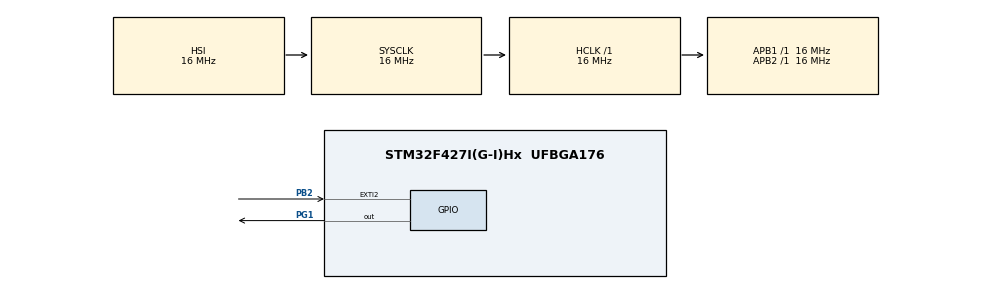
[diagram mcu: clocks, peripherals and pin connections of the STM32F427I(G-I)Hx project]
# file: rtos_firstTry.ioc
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FREERTOS.Tasks01=LEDTask,-3,128,LED_Task,Default,NULL,Dynamic,NULL,NULL;keyTask,-3,128,key_Task,Default,NULL,Dynamic,NULL,NULL
Mcu.Family=STM32F4
Mcu.Name=STM32F427I(G-I)Hx
Mcu.Package=UFBGA176
NVIC.EXTI2_IRQn=true\:5\:0\:false\:false\:true\:true\:true\:true
NVIC.PriorityGroup=NVIC_PRIORITYGROUP_4
NVIC.TIM1_UP_TIM10_IRQn=true\:0\:0\:false\:false\:true\:false\:false\:true
NVIC.TimeBase=TIM1_UP_TIM10_IRQn
NVIC.TimeBaseIP=TIM1
PA13.Mode=Serial_Wire
PA13.Signal=SYS_JTMS-SWDIO
PA14.Mode=Serial_Wire
PA14.Signal=SYS_JTCK-SWCLK
PB2/BOOT1.GPIO_ModeDefaultEXTI=GPIO_MODE_IT_RISING_FALLING
PB2/BOOT1.Signal=GPXTI2
PG1.Signal=GPIO_Output
ProjectManager.HeapSize=0x200
ProjectManager.StackSize=0x400
ProjectManager.TargetToolchain=MDK-ARM V5
RCC.AHBFreq_Value=16000000
RCC.APB1Freq_Value=16000000
RCC.APB2Freq_Value=16000000
RCC.CortexFreq_Value=16000000
RCC.HSE_VALUE=25000000
RCC.HSI_VALUE=16000000
RCC.LSE_VALUE=32768
RCC.SYSCLKFreq_VALUE=16000000
RCC.VCOOutputFreq_Value=192000000
VP_FREERTOS_VS_CMSIS_V1.Mode=CMSIS_V1
VP_SYS_VS_tim1.Mode=TIM1
board=custom

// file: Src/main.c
/* USER CODE BEGIN Header */
/**
  ******************************************************************************
  * @file           : main.c
  * @brief          : Main program body
  ******************************************************************************
  * @attention
  *
  * <h2><center>&copy; Copyright (c) 2022 STMicroelectronics.
  * All rights reserved.</center></h2>
  *
  * This software component is licensed by ST under Ultimate Liberty license
  * SLA0044, the "License"; You may not use this file except in compliance with
  * the License. You may obtain a copy of the License at:
  *                             www.st.com/SLA0044
  *
  ******************************************************************************
  */
/* USER CODE END Header */

#include "main.h"
#include "cmsis_os.h"
#include "gpio.h"

void SystemClock_Config(void);
void MX_FREERTOS_Init(void);

int main(void)
{

  /* MCU Configuration--------------------------------------------------------*/

  /* Reset of all peripherals, Initializes the Flash interface and the Systick. */
  HAL_Init();

  /* Configure the system clock */
  SystemClock_Config();

  /* Initialize all configured peripherals */
  MX_GPIO_Init();

  /* Call init function for freertos objects (in freertos.c) */
  MX_FREERTOS_Init();

  /* Start scheduler */
  osKernelStart();

  /* We should never get here as control is now taken by the scheduler */

  /* Infinite loop */
  while (1)
  {

    /* USER CODE BEGIN 3 */
		//printf("Uart Task is Runing!\r\n");
  }
  /* USER CODE END 3 */
}

void SystemClock_Config(void)
{
  RCC_OscInitTypeDef RCC_OscInitStruct = {0};
  RCC_ClkInitTypeDef RCC_ClkInitStruct = {0};

  /** Configure the main internal regulator output voltage
  */
  __HAL_RCC_PWR_CLK_ENABLE();
  __HAL_PWR_VOLTAGESCALING_CONFIG(PWR_REGULATOR_VOLTAGE_SCALE3);
  /** Initializes the CPU, AHB and APB busses clocks
  */
  RCC_OscInitStruct.OscillatorType = RCC_OSCILLATORTYPE_HSI;
  RCC_OscInitStruct.HSIState = RCC_HSI_ON;
  RCC_OscInitStruct.HSICalibrationValue = RCC_HSICALIBRATION_DEFAULT;
  RCC_OscInitStruct.PLL.PLLState = RCC_PLL_NONE;
  if (HAL_RCC_OscConfig(&RCC_OscInitStruct) != HAL_OK)
  {
    Error_Handler();
  }
  /** Initializes the CPU, AHB and APB busses clocks
  */
  RCC_ClkInitStruct.ClockType = RCC_CLOCKTYPE_HCLK|RCC_CLOCKTYPE_SYSCLK
                              |RCC_CLOCKTYPE_PCLK1|RCC_CLOCKTYPE_PCLK2;
  RCC_ClkInitStruct.SYSCLKSource = RCC_SYSCLKSOURCE_HSI;
  RCC_ClkInitStruct.AHBCLKDivider = RCC_SYSCLK_DIV1;
  RCC_ClkInitStruct.APB1CLKDivider = RCC_HCLK_DIV1;
  RCC_ClkInitStruct.APB2CLKDivider = RCC_HCLK_DIV1;

  if (HAL_RCC_ClockConfig(&RCC_ClkInitStruct, FLASH_LATENCY_0) != HAL_OK)
  {
    Error_Handler();
  }
}

void HAL_TIM_PeriodElapsedCallback(TIM_HandleTypeDef *htim)
{
  if (htim->Instance == TIM1) {
    HAL_IncTick();
  }
}

void Error_Handler(void)
{
}

/************************ (C) COPYRIGHT STMicroelectronics *****END OF FILE****/

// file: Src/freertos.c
/* USER CODE BEGIN Header */
/**
  ******************************************************************************
  * File Name          : freertos.c
  * Description        : Code for freertos applications
  ******************************************************************************
  * @attention
  *
  * <h2><center>&copy; Copyright (c) 2022 STMicroelectronics.
  * All rights reserved.</center></h2>
  *
  * This software component is licensed by ST under Ultimate Liberty license
  * SLA0044, the "License"; You may not use this file except in compliance with
  * the License. You may obtain a copy of the License at:
  *                             www.st.com/SLA0044
  *
  ******************************************************************************
  */
/* USER CODE END Header */

#include "FreeRTOS.h"
#include "task.h"
#include "main.h"
#include "cmsis_os.h"

/* USER CODE BEGIN Includes */
#include "gpio.h"
/* USER CODE END Includes */

/* USER CODE BEGIN Variables */
extern Key_Status KeyStatus;
/* USER CODE END Variables */
osThreadId LEDTaskHandle;
osThreadId keyTaskHandle;

void LED_Task(void const * argument);
void key_Task(void const * argument);

void MX_FREERTOS_Init(void); /* (MISRA C 2004 rule 8.1) */

/* GetIdleTaskMemory prototype (linked to static allocation support) */
void vApplicationGetIdleTaskMemory( StaticTask_t **ppxIdleTaskTCBBuffer, StackType_t **ppxIdleTaskStackBuffer, uint32_t *pulIdleTaskStackSize );

/* USER CODE BEGIN GET_IDLE_TASK_MEMORY */
static StaticTask_t xIdleTaskTCBBuffer;
static StackType_t xIdleStack[configMINIMAL_STACK_SIZE];

void vApplicationGetIdleTaskMemory( StaticTask_t **ppxIdleTaskTCBBuffer, StackType_t **ppxIdleTaskStackBuffer, uint32_t *pulIdleTaskStackSize )
{
  *ppxIdleTaskTCBBuffer = &xIdleTaskTCBBuffer;
  *ppxIdleTaskStackBuffer = &xIdleStack[0];
  *pulIdleTaskStackSize = configMINIMAL_STACK_SIZE;
  /* place for user code */
}
/* USER CODE END GET_IDLE_TASK_MEMORY */

void MX_FREERTOS_Init(void) {

  /* Create the thread(s) */
  /* definition and creation of LEDTask */
  osThreadDef(LEDTask, LED_Task, osPriorityIdle, 0, 128);
  LEDTaskHandle = osThreadCreate(osThread(LEDTask), NULL);

  /* definition and creation of keyTask */
  osThreadDef(keyTask, key_Task, osPriorityIdle, 0, 128);
  keyTaskHandle = osThreadCreate(osThread(keyTask), NULL);

}

void LED_Task(void const * argument)
{

  /* USER CODE BEGIN LED_Task */
  /* Infinite loop */
  for(;;)
  {
		HAL_GPIO_WritePin(GPIOG, GPIO_PIN_1, 1);
    osDelay(500);
		HAL_GPIO_WritePin(GPIOG, GPIO_PIN_1, 0);
    osDelay(500);
  }
  /* USER CODE END LED_Task */
}

void key_Task(void const * argument)
{
  /* USER CODE BEGIN key_Task */
  /* Infinite loop */
  for(;;)
  {
		if(KeyStatus ==KEY_DOWN)
		{
			vTaskSuspend(LEDTaskHandle);		//任务挂起
			KeyStatus = KEY_UNKNOW;
		}
		else if(KeyStatus ==KEY_UP)
		{
			vTaskResume(LEDTaskHandle);			//任务恢复，参数为对应任务的句柄（往上翻）
			KeyStatus = KEY_UNKNOW;					//中断标志位回复，按住和松开，按键要配置上升沿和下降沿
		}

    osDelay(10);
  }
  /* USER CODE END key_Task */
}

/************************ (C) COPYRIGHT STMicroelectronics *****END OF FILE****/
